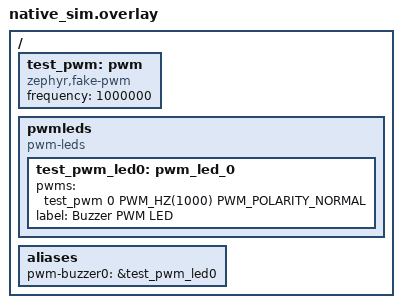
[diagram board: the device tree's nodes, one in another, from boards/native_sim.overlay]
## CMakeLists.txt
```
# SPDX-FileCopyrightText: 2025 Alicipy <dev@stefankraus.org>
#
# SPDX-License-Identifier: Apache-2.0

cmake_minimum_required(VERSION 3.20.0)

find_package(Zephyr REQUIRED HINTS $ENV{ZEPHYR_BASE})
project(aldrin_buzzer_test)

target_sources(app PRIVATE
        ${CMAKE_CURRENT_SOURCE_DIR}/src/test_aldrin.c
        ${ZEPHYR_COFFEECALLER_MODULE_DIR}/lib/cc_lib/aldrin.c
)
```

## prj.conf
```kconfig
# SPDX-FileCopyrightText: 2025 Alicipy <dev@stefankraus.org>
#
# SPDX-License-Identifier: Apache-2.0

CONFIG_ZTEST=y
CONFIG_PWM=y
```

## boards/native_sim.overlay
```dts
/*
 * SPDX-FileCopyrightText: 2025 Alicipy <dev@stefankraus.org>
 *
 * SPDX-License-Identifier: Apache-2.0
 */

#include <zephyr/dt-bindings/pwm/pwm.h>

/ {

	test_pwm: pwm {
		compatible = "zephyr,fake-pwm";
		#pwm-cells = <2>;
		frequency = <1000000>;
		status = "okay";
	};

	pwmleds {
		compatible = "pwm-leds";

		test_pwm_led0: pwm_led_0 {
			pwms = <&test_pwm 0 PWM_HZ(1000) PWM_POLARITY_NORMAL>;
			label = "Buzzer PWM LED";
		};
	};



	aliases {
		pwm-buzzer0 = &test_pwm_led0;
	};
};
```

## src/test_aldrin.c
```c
/*
 * SPDX-FileCopyrightText: 2025 Alicipy <dev@stefankraus.org>
 *
 * SPDX-License-Identifier: Apache-2.0
 */

#include <zephyr/ztest.h>
#include <zephyr/kernel.h>
#include <zephyr/fff.h>

#include <cc_lib/aldrin.h>

#include <zephyr/drivers/pwm/pwm_fake.h>

DEFINE_FFF_GLOBALS;

static void before_test_setup(void* f)
{
    aldrin_init();
}

ZTEST_SUITE(aldrin_tests, NULL, NULL, before_test_setup, NULL, NULL);

ZTEST(aldrin_tests, test__buzz_short)
{
    zassert_equal(fake_pwm_set_cycles_fake.call_count, 0);
    aldrin_buzz_short();

    zassert_equal(fake_pwm_set_cycles_fake.call_count, 1,
                  "PWM should be called once, but was %d!",
                  fake_pwm_set_cycles_fake.call_count);
    zassert_not_equal(fake_pwm_set_cycles_fake.arg2_val, 0,
                      "Period cycles should not be 0, but is!");
    zassert_not_equal(fake_pwm_set_cycles_fake.arg3_val, 0,
                      "Pulse cycles should not be 0, but is!");

    // give stop timer some time to fire.
    k_sleep(K_MSEC(300));

    zassert_equal(fake_pwm_set_cycles_fake.call_count, 2,
                  "PWM should be called twice now, but was %d!",
                  fake_pwm_set_cycles_fake.call_count);
    zassert_equal(fake_pwm_set_cycles_fake.arg3_val, 0,
                  "Pulse cycles should be 0 now, but was %d!",
                  fake_pwm_set_cycles_fake.arg3_val);
}
```
